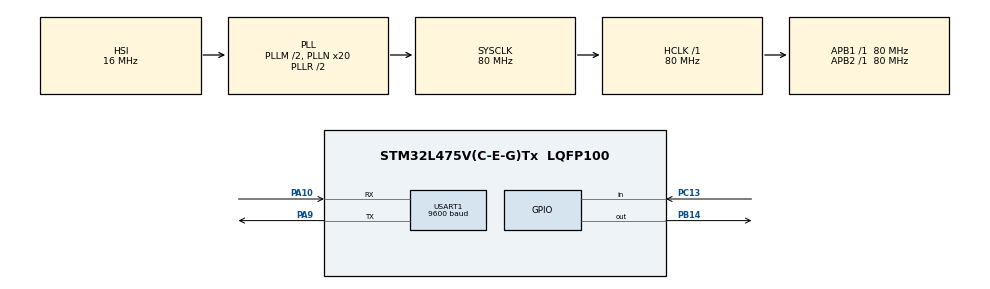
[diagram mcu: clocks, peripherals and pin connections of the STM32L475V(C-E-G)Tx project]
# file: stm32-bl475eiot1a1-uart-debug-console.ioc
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Mcu.Family=STM32L4
Mcu.Name=STM32L475V(C-E-G)Tx
Mcu.Package=LQFP100
NVIC.PriorityGroup=NVIC_PRIORITYGROUP_4
PA10.Mode=Asynchronous
PA10.Signal=USART1_RX
PA9.Mode=Asynchronous
PA9.Signal=USART1_TX
PB14.Signal=GPIO_Output
PC13.GPIO_PuPd=GPIO_PULLUP
PC13.Signal=GPIO_Input
PC14-OSC32_IN\ (PC14).Mode=LSE-External-Clock-Source
PC14-OSC32_IN\ (PC14).Signal=RCC_OSC32_IN
ProjectManager.HeapSize=0x200
ProjectManager.StackSize=0x400
ProjectManager.TargetToolchain=STM32CubeIDE
RCC.ADCFreq_Value=192000000
RCC.AHBFreq_Value=80000000
RCC.APB1Freq_Value=80000000
RCC.APB1TimFreq_Value=80000000
RCC.APB2Freq_Value=80000000
RCC.APB2TimFreq_Value=80000000
RCC.CortexFreq_Value=80000000
RCC.HCLKFreq_Value=80000000
RCC.HSE_VALUE=8000000
RCC.HSI_VALUE=16000000
RCC.LSE_VALUE=32768
RCC.MSI_VALUE=4000000
RCC.PLLN=20
RCC.PLLR=RCC_PLLR_DIV4
RCC.PLLSAI1N=24
RCC.PLLSourceVirtual=RCC_PLLSOURCE_HSI
RCC.SYSCLKFreq_VALUE=80000000
RCC.SYSCLKSource=RCC_SYSCLKSOURCE_PLLCLK
RCC.USBFreq_Value=192000000
RCC.VCOOutputFreq_Value=320000000
USART1.BaudRate=9600
USART1.VirtualMode-Asynchronous=VM_ASYNC
board=B-L475E-IOT01A1

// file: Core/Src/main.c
/* USER CODE BEGIN Header */
/**
  ******************************************************************************
  * @file           : main.c
  * @brief          : Main program body
  ******************************************************************************
  * @attention
  *
  * Copyright (c) 2026 STMicroelectronics.
  * All rights reserved.
  *
  * This software is licensed under terms that can be found in the LICENSE file
  * in the root directory of this software component.
  * If no LICENSE file comes with this software, it is provided AS-IS.
  *
  ******************************************************************************
  */
/* USER CODE END Header */
#include "main.h"
#include "uart_console.h"

UART_HandleTypeDef huart1;

void SystemClock_Config(void);
static void MX_GPIO_Init(void);
static void MX_USART1_UART_Init(void);

int main(void)
{

  /* MCU Configuration--------------------------------------------------------*/

  /* Reset of all peripherals, Initializes the Flash interface and the Systick. */
  HAL_Init();

  /* Configure the system clock */
  SystemClock_Config();

  /* Initialize all configured peripherals */
  MX_GPIO_Init();
  MX_USART1_UART_Init();
  /* USER CODE BEGIN 2 */
  UART_Console_Init(&huart1);

  /* USER CODE END 2 */

  /* Infinite loop */
  /* USER CODE BEGIN WHILE */
  while (1)
  {

	  UART_Console_Print("Hi Gurnoor Did It.", HAL_GetTick());

	  HAL_Delay(1000);

    /* USER CODE END WHILE */

  }
}

void SystemClock_Config(void)
{
  RCC_OscInitTypeDef RCC_OscInitStruct = {0};
  RCC_ClkInitTypeDef RCC_ClkInitStruct = {0};

  HAL_PWREx_ControlVoltageScaling(PWR_REGULATOR_VOLTAGE_SCALE1);

  RCC_OscInitStruct.OscillatorType = RCC_OSCILLATORTYPE_HSI;
  RCC_OscInitStruct.HSIState = RCC_HSI_ON;
  RCC_OscInitStruct.HSICalibrationValue = RCC_HSICALIBRATION_DEFAULT;

  RCC_OscInitStruct.PLL.PLLState = RCC_PLL_ON;
  RCC_OscInitStruct.PLL.PLLSource = RCC_PLLSOURCE_HSI;
  RCC_OscInitStruct.PLL.PLLM = 2;
  RCC_OscInitStruct.PLL.PLLN = 20;
  RCC_OscInitStruct.PLL.PLLR = RCC_PLLR_DIV2;
  RCC_OscInitStruct.PLL.PLLP = RCC_PLLP_DIV7;
  RCC_OscInitStruct.PLL.PLLQ = RCC_PLLQ_DIV2;

  if (HAL_RCC_OscConfig(&RCC_OscInitStruct) != HAL_OK)
  {
    Error_Handler();
  }

  RCC_ClkInitStruct.ClockType =
      RCC_CLOCKTYPE_SYSCLK |
      RCC_CLOCKTYPE_HCLK   |
      RCC_CLOCKTYPE_PCLK1  |
      RCC_CLOCKTYPE_PCLK2;

  RCC_ClkInitStruct.SYSCLKSource = RCC_SYSCLKSOURCE_PLLCLK;
  RCC_ClkInitStruct.AHBCLKDivider = RCC_SYSCLK_DIV1;
  RCC_ClkInitStruct.APB1CLKDivider = RCC_HCLK_DIV1;
  RCC_ClkInitStruct.APB2CLKDivider = RCC_HCLK_DIV1;

  if (HAL_RCC_ClockConfig(&RCC_ClkInitStruct, FLASH_LATENCY_4) != HAL_OK)
  {
    Error_Handler();
  }
}

static void MX_USART1_UART_Init(void)
{

  huart1.Instance = USART1;
  huart1.Init.BaudRate = 115200;
  huart1.Init.WordLength = UART_WORDLENGTH_8B;
  huart1.Init.StopBits = UART_STOPBITS_1;
  huart1.Init.Parity = UART_PARITY_NONE;
  huart1.Init.Mode = UART_MODE_TX_RX;
  huart1.Init.HwFlowCtl = UART_HWCONTROL_NONE;
  huart1.Init.OverSampling = UART_OVERSAMPLING_16;
  huart1.Init.OneBitSampling = UART_ONE_BIT_SAMPLE_DISABLE;
  huart1.AdvancedInit.AdvFeatureInit = UART_ADVFEATURE_NO_INIT;
  if (HAL_UART_Init(&huart1) != HAL_OK)
  {
    Error_Handler();
  }

}

static void MX_GPIO_Init(void)
{
  GPIO_InitTypeDef GPIO_InitStruct = {0};

  /* GPIO Ports Clock Enable */
  __HAL_RCC_GPIOC_CLK_ENABLE();
  __HAL_RCC_GPIOB_CLK_ENABLE();
  __HAL_RCC_GPIOA_CLK_ENABLE();

  /*Configure GPIO pin Output Level */
  HAL_GPIO_WritePin(GPIOB, GPIO_PIN_14, GPIO_PIN_RESET);

  /*Configure GPIO pin : PC13 */
  GPIO_InitStruct.Pin = GPIO_PIN_13;
  GPIO_InitStruct.Mode = GPIO_MODE_INPUT;
  GPIO_InitStruct.Pull = GPIO_PULLUP;
  HAL_GPIO_Init(GPIOC, &GPIO_InitStruct);

  /*Configure GPIO pin : PB14 */
  GPIO_InitStruct.Pin = GPIO_PIN_14;
  GPIO_InitStruct.Mode = GPIO_MODE_OUTPUT_PP;
  GPIO_InitStruct.Pull = GPIO_NOPULL;
  GPIO_InitStruct.Speed = GPIO_SPEED_FREQ_LOW;
  HAL_GPIO_Init(GPIOB, &GPIO_InitStruct);

  /* USER CODE BEGIN MX_GPIO_Init_2 */
  /* Configure USART1 GPIO pins */
  GPIO_InitStruct.Pin = GPIO_PIN_6 | GPIO_PIN_7;
  GPIO_InitStruct.Mode = GPIO_MODE_AF_PP;
  GPIO_InitStruct.Pull = GPIO_NOPULL;
  GPIO_InitStruct.Speed = GPIO_SPEED_FREQ_VERY_HIGH;
  GPIO_InitStruct.Alternate = GPIO_AF7_USART1;
  HAL_GPIO_Init(GPIOB, &GPIO_InitStruct);

  /* USER CODE END MX_GPIO_Init_2 */
}

void Error_Handler(void)
{
  __disable_irq();
  while (1)
  {
  }
}
